# STM32F103 register map
File version: 1.0
CPU: CM3 r1p1, little endian, 4 interrupt priority bits
Registers are 32-bit, read-write, reset 0xFCFCFCFC unless marked. A register's access mark holds for its fields unless they carry their own. Offsets are from the block's base; lines under a group give offsets from that group; [hi:lo] are bit positions; {n}, {i} and the like mark numbered series; 'fields as' and 'values as' point back to an identical list; <NAME> marks a mode.

## Memory map
0xA0000000 FSMC size 0x1000 — Flexible static memory controller

## Interrupts
48 FSMC — FSMC global interrupt

## FSMC — Flexible static memory controller
Base 0xA0000000
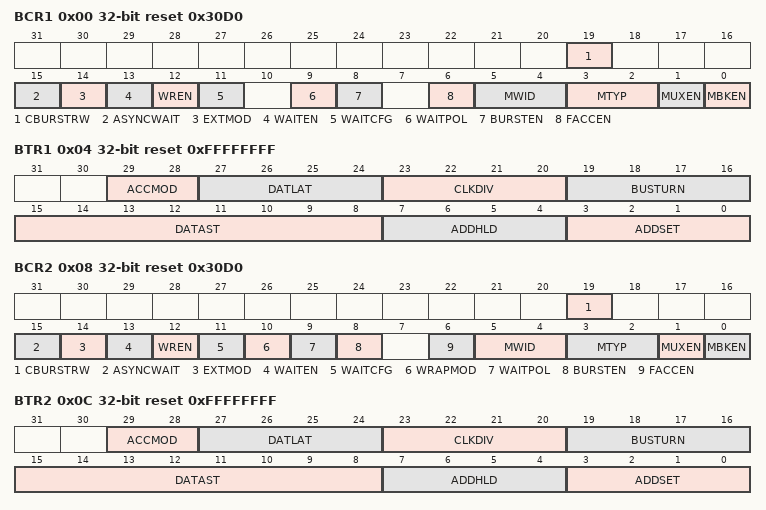
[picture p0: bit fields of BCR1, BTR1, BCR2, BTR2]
0x00 BCR1 reset 0x30D0 — SRAM/NOR-Flash chip-select control register 1
  [19] CBURSTRW, [15] ASYNCWAIT, [14] EXTMOD, [13] WAITEN, [12] WREN, [11] WAITCFG, [9] WAITPOL, [8] BURSTEN, [6] FACCEN, [5:4] MWID, [3:2] MTYP, [1] MUXEN, [0] MBKEN
0x04 BTR1 reset 0xFFFFFFFF — SRAM/NOR-Flash chip-select timing register 1
  [29:28] ACCMOD, [27:24] DATLAT, [23:20] CLKDIV, [19:16] BUSTURN, [15:8] DATAST, [7:4] ADDHLD, [3:0] ADDSET
0x08 BCR2 reset 0x30D0 — SRAM/NOR-Flash chip-select control register 2
  [19] CBURSTRW, [15] ASYNCWAIT, [14] EXTMOD, [13] WAITEN, [12] WREN, [11] WAITCFG, [10] WRAPMOD, [9] WAITPOL, [8] BURSTEN, [6] FACCEN, [5:4] MWID, [3:2] MTYP, [1] MUXEN, [0] MBKEN
0x0C BTR2 reset 0xFFFFFFFF — SRAM/NOR-Flash chip-select timing register 2
  fields as BTR1
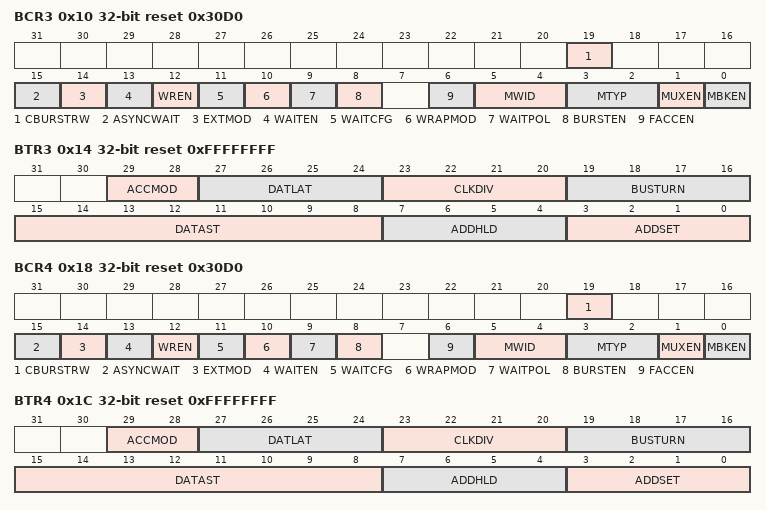
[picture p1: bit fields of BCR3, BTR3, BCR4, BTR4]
0x10 BCR3 reset 0x30D0 — SRAM/NOR-Flash chip-select control register 3
  fields as BCR2
0x14 BTR3 reset 0xFFFFFFFF — SRAM/NOR-Flash chip-select timing register 3
  fields as BTR1
0x18 BCR4 reset 0x30D0 — SRAM/NOR-Flash chip-select control register 4
  fields as BCR2
0x1C BTR4 reset 0xFFFFFFFF — SRAM/NOR-Flash chip-select timing register 4
  fields as BTR1
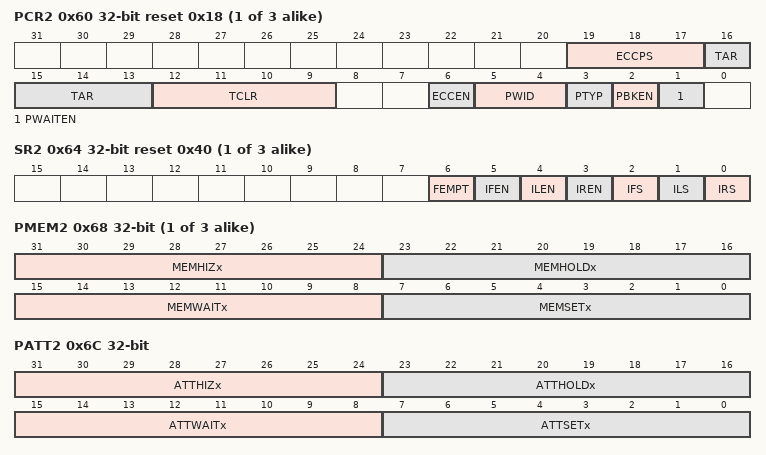
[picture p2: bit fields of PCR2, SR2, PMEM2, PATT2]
{0x20+0x20*i} PCR{i} reset 0x18 (i=2..4) — PC Card/NAND Flash control register {i}
  [19:17] ECCPS, [16:13] TAR, [12:9] TCLR, [6] ECCEN, [5:4] PWID, [3] PTYP, [2] PBKEN, [1] PWAITEN
{0x24+0x20*i} SR{i} access per field reset 0x40 (i=2..4) — FIFO status and interrupt register {i}
  [6] FEMPT ro, [5] IFEN rw, [4] ILEN rw, [3] IREN rw, [2] IFS rw, [1] ILS rw, [0] IRS rw
{0x28+0x20*i} PMEM{i} (i=2..4) — Common memory space timing register {i}
  [31:24] MEMHIZx, [23:16] MEMHOLDx, [15:8] MEMWAITx, [7:0] MEMSETx
0x6C PATT2 — Attribute memory space timing register 2
  [31:24] ATTHIZx — Attribute memory x databus HiZ time
  [23:16] ATTHOLDx — Attribute memory x hold time
  [15:8] ATTWAITx — Attribute memory x wait time
  [7:0] ATTSETx — Attribute memory x setup time
0x74 ECCR2 ro reset 0x0 — ECC result register 2
  [31:0] ECCx — ECC result
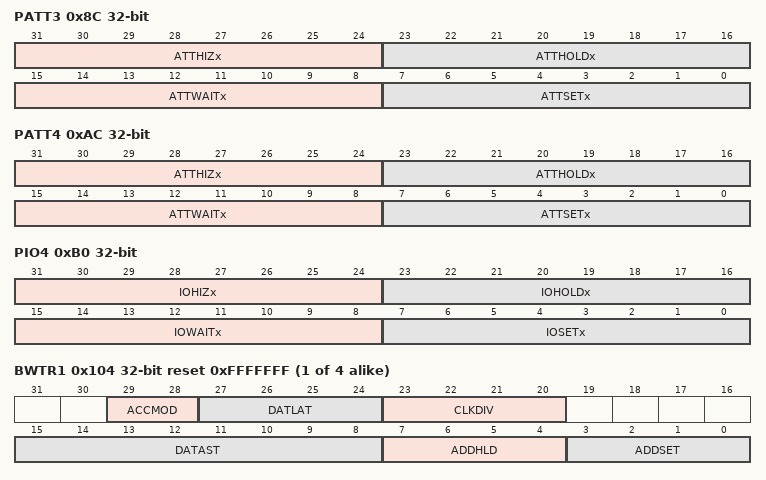
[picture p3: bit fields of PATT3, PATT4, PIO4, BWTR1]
0x8C PATT3 — Attribute memory space timing register 3
  [31:24] ATTHIZx, [23:16] ATTHOLDx, [15:8] ATTWAITx, [7:0] ATTSETx
0x94 ECCR3 ro reset 0x0 — ECC result register 3
  [31:0] ECCx
0xAC PATT4 — Attribute memory space timing register 4
  [31:24] ATTHIZx, [23:16] ATTHOLDx, [15:8] ATTWAITx, [7:0] ATTSETx
0xB0 PIO4 — I/O space timing register 4
  [31:24] IOHIZx, [23:16] IOHOLDx, [15:8] IOWAITx, [7:0] IOSETx
{0xFC+8i} BWTR{i} reset 0xFFFFFFF (i=1..4) — SRAM/NOR-Flash write timing registers {i}
  [29:28] ACCMOD, [27:24] DATLAT, [23:20] CLKDIV, [15:8] DATAST, [7:4] ADDHLD, [3:0] ADDSET
